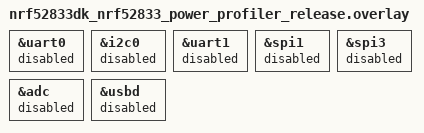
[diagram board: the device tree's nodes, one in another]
&uart0 {
	status = "disabled";
};
&i2c0 {
	status = "disabled";
};
&uart1 {
	status = "disabled";
};
&spi1 {
	status = "disabled";
};
&spi3 {
	status = "disabled";
};
&adc {
	status = "disabled";
};
&usbd {
	status = "disabled";
};
